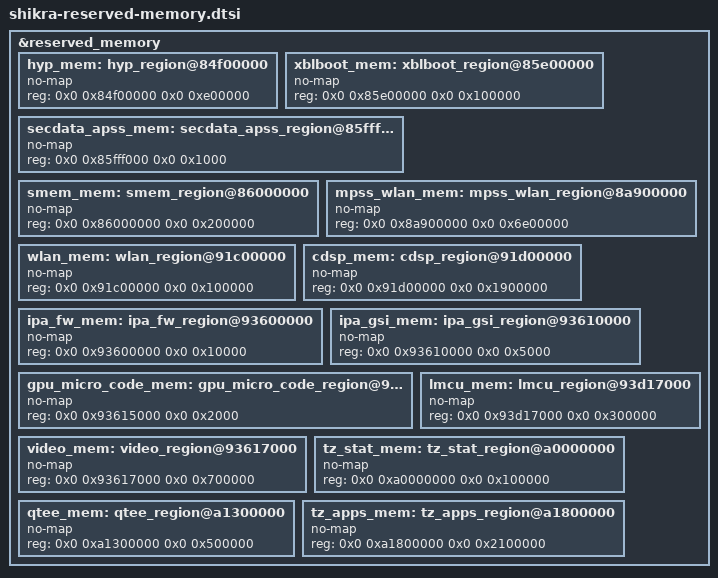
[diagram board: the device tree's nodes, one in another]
// SPDX-License-Identifier: BSD-3-Clause
/*
 * Copyright (c) Qualcomm Technologies, Inc. and/or its subsidiaries.
 */

&reserved_memory {
	#address-cells = <2>;
	#size-cells = <2>;
	ranges;

	hyp_mem: hyp_region@84f00000 {
		no-map;
		reg = <0x0 0x84f00000 0x0 0xe00000>;
	};

	xblboot_mem: xblboot_region@85e00000 {
		no-map;
		reg = <0x0 0x85e00000 0x0 0x100000>;
	};

	secdata_apss_mem: secdata_apss_region@85fff000 {
		no-map;
		reg = <0x0 0x85fff000 0x0 0x1000>;
	};

	smem_mem: smem_region@86000000 {
		no-map;
		reg = <0x0 0x86000000 0x0 0x200000>;
	};

	mpss_wlan_mem: mpss_wlan_region@8a900000 {
		no-map;
		reg = <0x0 0x8a900000 0x0 0x6e00000>;
	};

	wlan_mem: wlan_region@91c00000 {
		no-map;
		reg = <0x0 0x91c00000 0x0 0x100000>;
	};

	cdsp_mem: cdsp_region@91d00000 {
		no-map;
		reg = <0x0 0x91d00000 0x0 0x1900000>;
	};

	ipa_fw_mem: ipa_fw_region@93600000 {
		no-map;
		reg = <0x0 0x93600000 0x0 0x10000>;
	};

	ipa_gsi_mem: ipa_gsi_region@93610000 {
		no-map;
		reg = <0x0 0x93610000 0x0 0x5000>;
	};

	gpu_micro_code_mem: gpu_micro_code_region@93615000 {
		no-map;
		reg = <0x0 0x93615000 0x0 0x2000>;
	};

	video_mem: video_region@93617000 {
		no-map;
		reg = <0x0 0x93617000 0x0 0x700000>;
	};

	lmcu_mem: lmcu_region@93d17000 {
		no-map;
		reg = <0x0 0x93d17000 0x0 0x300000>;
	};

	/* UEFI region at 0x9F800000 is reclaimed by Linux */
	tz_stat_mem: tz_stat_region@a0000000 {
		no-map;
		reg = <0x0 0xa0000000 0x0 0x100000>;
	};

	/* TA at 0xA0100000 is dynamically removed from the RAM
	 * partition tables before boot occurs.
	 */
	qtee_mem: qtee_region@a1300000 {
		no-map;
		reg = <0x0 0xa1300000 0x0 0x500000>;
	};

	tz_apps_mem: tz_apps_region@a1800000 {
		no-map;
		reg = <0x0 0xa1800000 0x0 0x2100000>;
	};

};
